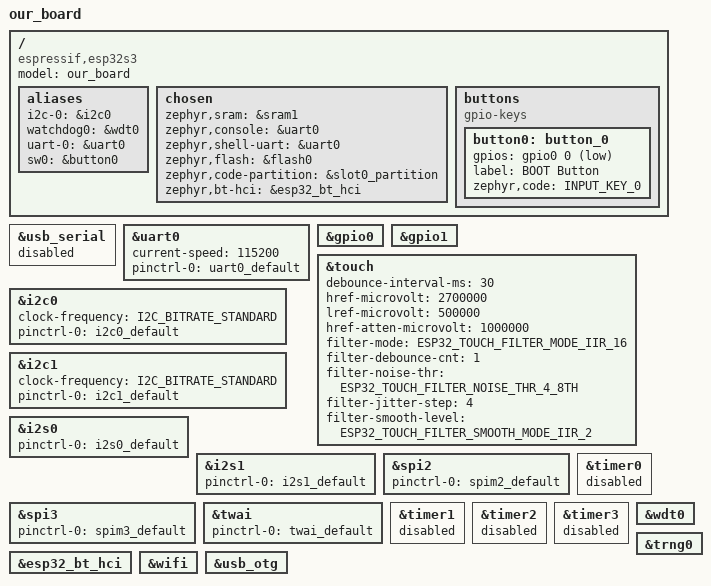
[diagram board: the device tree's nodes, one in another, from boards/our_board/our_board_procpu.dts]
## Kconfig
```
menuconfig LED_SUBSYSTEM
  bool "LED Subsystem"
  default y
  
if LED_SUBSYSTEM

choice 
  prompt "LED blink sleep time"
  default BLINK_SLEEP_1000MS

config BLINK_SLEEP_250MS
  bool "0.25s (Super Fast)"

config BLINK_SLEEP_500MS
  bool "0.5s (Fast)"

config BLINK_SLEEP_1000MS
  bool "1s (medium)"

config BLINK_SLEEP_2000MS
  bool "2s (Slow)"

endchoice

config BLINK_SLEEP_TIME_MS
    int 
    default 250 if BLINK_SLEEP_250MS
    default 500 if BLINK_SLEEP_500MS
    default 1000 if BLINK_SLEEP_1000MS
    default 1000 if BLINK_SLEEP_2000MS
    default 0
    help
      Time between LED toggles in miliseconds.

config APP_HEARTBEAT_PERIOD_MS
  int "APP HEARTBEAT PERIOD MS (100- 2000)"
  range 100 2000
  default 500
  help
    controls the blink speed of heartbeat led strip


menuconfig ADVANCED_LED_SETTINGS
  bool "Advanced LED settings"
  default n

if ADVANCED_LED_SETTINGS

config LED_BRIGHTNESS
  int "LED brightness (0-100)"
  default 100

config LED_FADE_DURATION
  int "LED fade duration (ms)"
  range 0 5000
  default 100

menu "Expert settings"
  visible if ADVANCED_LED_SETTINGS

config LED_DEBUG
  bool "Enable LED debugging"

config CUSTOM_LED_BLINK
  bool "Custom blink pattern"

endmenu


endif #ADVANCED_LED_SETTINGS

endif # LED_SUBSYSTEM

source "Kconfig.zephyr"
rsource "drivers/our_driver/Kconfig"
```

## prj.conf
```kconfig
CONFIG_GPIO=y
CONFIG_LOG=y
CONFIG_LED_STRIP=y
CONFIG_HEAP_MEM_POOL_SIZE=4096
CONFIG_OUR_DRIVER=y
CONFIG_CONSOLE=y
CONFIG_SERIAL=y
CONFIG_UART_CONSOLE=y
```

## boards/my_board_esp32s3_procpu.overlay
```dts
#include <dt-bindings/led/led.h>


/ {
	aliases {
		app-led = &led_strip;
	};

	led_strip: ws2812 {
		compatible = "worldsemi,ws2812-pulse-io";
		pulse-ios = <&rmt 0>;
		chain-length = <1>;
		color-mapping = <LED_COLOR_ID_GREEN
				 LED_COLOR_ID_RED
				 LED_COLOR_ID_BLUE>;
		reset-delay = <300>;
	};

	our_driver_inst: our_driver_inst {
		compatible = "our,driver";
		status = "okay";
	};


};

&pinctrl {
	rmt_ws2812: rmt_ws2812 {
		group1 {
			pinmux = <RMT_OUT0_GPIO48>;
		};
	};
};

&rmt {
	pinctrl-0 = <&rmt_ws2812>;
	pinctrl-names = "default";
	status = "okay";
};
```

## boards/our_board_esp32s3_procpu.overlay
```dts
#include <dt-bindings/led/led.h>

/ {
	aliases {
		app-led = &led_strip;
	};

	led_strip: ws2812 {
		compatible = "worldsemi,ws2812-pulse-io";
		pulse-ios = <&rmt 0>;
		chain-length = <1>;
		color-mapping = <LED_COLOR_ID_GREEN
				 LED_COLOR_ID_RED
				 LED_COLOR_ID_BLUE>;
		reset-delay = <300>;
	};
};

&pinctrl {
	rmt_ws2812: rmt_ws2812 {
		group1 {
			pinmux = <RMT_OUT0_GPIO48>;
		};
	};
};

&rmt {
	pinctrl-0 = <&rmt_ws2812>;
	pinctrl-names = "default";
	status = "okay";
};
```

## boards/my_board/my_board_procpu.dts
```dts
/dts-v1/;

#include <espressif/esp32s3/esp32s3_wroom_n8.dtsi>
#include <espressif/partitions_0x0_amp.dtsi>
#include "esp32s3_devkitc-pinctrl.dtsi"



/{
	model = "our_board";
	compatible = "espressif,esp32s3";

	aliases {
	};

	chosen {
		zephyr,sram = &sram1;
		zephyr,console = &uart0;
		zephyr,flash = &flash0;
		zephyr,code-partition = &slot0_partition;
	};


};

&uart0 {
	status = "okay";
	current-speed = <115200>;
	pinctrl-0 = <&uart0_default>;
	pinctrl-names = "default";
};
```

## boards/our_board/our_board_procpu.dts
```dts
/*
 * Copyright (c) 2024-2025 Espressif Systems (Shanghai) Co., Ltd.
 *
 * SPDX-License-Identifier: Apache-2.0
 */
/dts-v1/;

#include <espressif/esp32s3/esp32s3_wroom_n8.dtsi>
#include <zephyr/dt-bindings/input/input-event-codes.h>
#include <zephyr/dt-bindings/input/esp32-touch-sensor-input.h>
#include <espressif/partitions_0x0_amp.dtsi>
#include "esp32s3_devkitc-pinctrl.dtsi"

/ {
	model = "our_board";
	compatible = "espressif,esp32s3";

	aliases {
		i2c-0 = &i2c0;
		watchdog0 = &wdt0;
		uart-0 = &uart0;
		sw0 = &button0;
	};

	chosen {
		zephyr,sram = &sram1;
		zephyr,console = &uart0;
		zephyr,shell-uart = &uart0;
		zephyr,flash = &flash0;
		zephyr,code-partition = &slot0_partition;
		zephyr,bt-hci = &esp32_bt_hci;
	};

	buttons {
		compatible = "gpio-keys";

		button0: button_0 {
			gpios = <&gpio0 0 (GPIO_PULL_UP | GPIO_ACTIVE_LOW)>;
			label = "BOOT Button";
			zephyr,code = <INPUT_KEY_0>;
		};
	};
};

&usb_serial {
	status = "disabled";
};

&uart0 {
	status = "okay";
	current-speed = <115200>;
	pinctrl-0 = <&uart0_default>;
	pinctrl-names = "default";
};

&gpio0 {
	status = "okay";
};

&gpio1 {
	status = "okay";
};

&touch {
	debounce-interval-ms = <30>;
	href-microvolt = <2700000>;
	lref-microvolt = <500000>;
	href-atten-microvolt = <1000000>;
	filter-mode = <ESP32_TOUCH_FILTER_MODE_IIR_16>;
	filter-debounce-cnt = <1>;
	filter-noise-thr = <ESP32_TOUCH_FILTER_NOISE_THR_4_8TH>;
	filter-jitter-step = <4>;
	filter-smooth-level = <ESP32_TOUCH_FILTER_SMOOTH_MODE_IIR_2>;
};

&i2c0 {
	clock-frequency = <I2C_BITRATE_STANDARD>;
	pinctrl-0 = <&i2c0_default>;
	pinctrl-names = "default";
};

&i2c1 {
	clock-frequency = <I2C_BITRATE_STANDARD>;
	pinctrl-0 = <&i2c1_default>;
	pinctrl-names = "default";
};

&i2s0 {
	pinctrl-0 = <&i2s0_default>;
	pinctrl-names = "default";
};

&i2s1 {
	pinctrl-0 = <&i2s1_default>;
	pinctrl-names = "default";
};

&spi2 {
	#address-cells = <1>;
	#size-cells = <0>;
	status = "okay";
	pinctrl-0 = <&spim2_default>;
	pinctrl-names = "default";
};

&spi3 {
	#address-cells = <1>;
	#size-cells = <0>;
	status = "okay";
	pinctrl-0 = <&spim3_default>;
	pinctrl-names = "default";
};

&twai {
	pinctrl-0 = <&twai_default>;
	pinctrl-names = "default";
};

&timer0 {
	status = "disabled";
};

&timer1 {
	status = "disabled";
};

&timer2 {
	status = "disabled";
};

&timer3 {
	status = "disabled";
};

&wdt0 {
	status = "okay";
};

&trng0 {
	status = "okay";
};

&esp32_bt_hci {
	status = "okay";
};

&wifi {
	status = "okay";
};

zephyr_udc0: &usb_otg {
	status = "okay";
};

zephyr_uhc0: &usb_otg {
	status = "okay";
};
```

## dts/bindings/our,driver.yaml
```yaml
description: Our Simple GPIO driver
compatible: "our,driver"
include: base.yaml
```

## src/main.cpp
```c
#include <zephyr/drivers/led_strip.h>
#include <zephyr/kernel.h>
#include <zephyr/logging/log.h>
#include <string.h>
#include <zephyr/drivers/sensor.h>

extern "C" {
#include "../drivers/our_driver/our_driver_api.h"
}

#define LED_NODE DT_ALIAS(app_led)

static const struct device *strip = DEVICE_DT_GET(LED_NODE);
static struct led_rgb pixel;

LOG_MODULE_REGISTER(main, LOG_LEVEL_INF);

namespace {
  void test(){
    const struct device* driver = DEVICE_DT_GET(DT_NODELABEL(our_driver_inst));
    struct sensor_value val;
    int ret;

    /* Call custom extension API to change brightness */
    our_driver_set_brightness(driver, 0x05);

    ret = sensor_sample_fetch(driver);
    LOG_INF("Fetch ret %d", ret);

    ret = sensor_channel_get(driver, SENSOR_CHAN_ALL, &val);
    LOG_INF("Channel ret %d", ret);
  }
}

int main(void)
{
    LOG_INF("Board Initialized");
    test();
    bool led_state = true;

    if (!device_is_ready(strip)) return 0;

    while (1) {
        led_state = !led_state;
        memset(&pixel, 0, sizeof(pixel));
        pixel.g = led_state ? 0x20 : 0;
        led_strip_update_rgb(strip, &pixel, 1);
        LOG_INF("LED state: %s", led_state ? "ON" : "OFF");
        k_msleep(CONFIG_APP_HEARTBEAT_PERIOD_MS);
    }
    return 0;
}
```
